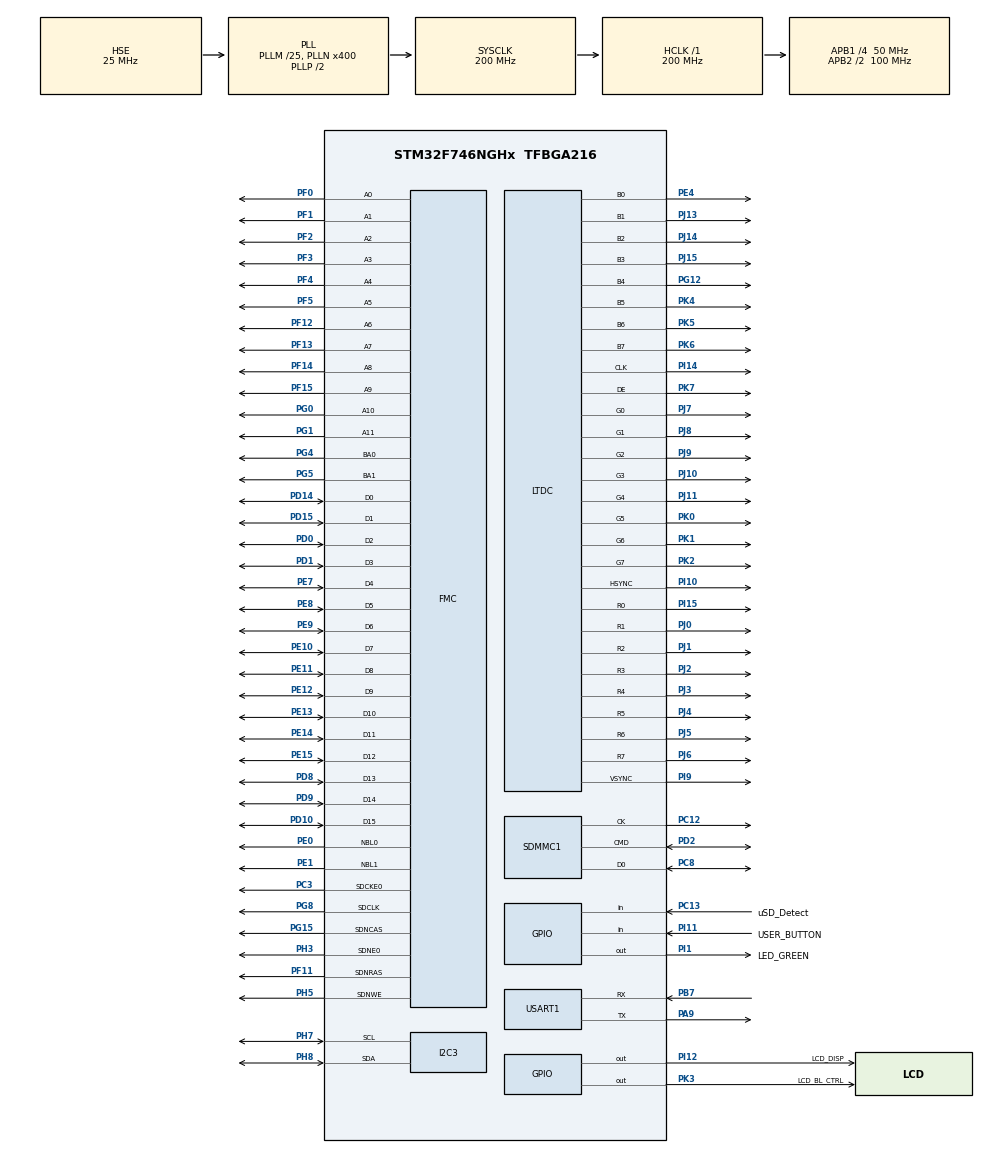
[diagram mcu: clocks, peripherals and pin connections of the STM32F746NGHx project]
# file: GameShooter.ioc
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CORTEX_M7.ART_ACCELERATOR_ENABLE=1
CORTEX_M7.AccessPermission-Cortex_Memory_Protection_Unit_Region0_Settings=MPU_REGION_NO_ACCESS
CORTEX_M7.AccessPermission-Cortex_Memory_Protection_Unit_Region1_Settings=MPU_REGION_FULL_ACCESS
CORTEX_M7.AccessPermission-Cortex_Memory_Protection_Unit_Region2_Settings=MPU_REGION_FULL_ACCESS
CORTEX_M7.BaseAddress-Cortex_Memory_Protection_Unit_Region0_Settings=0x00
CORTEX_M7.BaseAddress-Cortex_Memory_Protection_Unit_Region1_Settings=0xC0000000
CORTEX_M7.BaseAddress-Cortex_Memory_Protection_Unit_Region2_Settings=0xA0000000
CORTEX_M7.CPU_DCache=Enabled
CORTEX_M7.CPU_ICache=Enabled
CORTEX_M7.DisableExec-Cortex_Memory_Protection_Unit_Region0_Settings=MPU_INSTRUCTION_ACCESS_DISABLE
CORTEX_M7.DisableExec-Cortex_Memory_Protection_Unit_Region2_Settings=MPU_INSTRUCTION_ACCESS_DISABLE
CORTEX_M7.Enable-Cortex_Memory_Protection_Unit_Region0_Settings=MPU_REGION_ENABLE
CORTEX_M7.Enable-Cortex_Memory_Protection_Unit_Region1_Settings=MPU_REGION_ENABLE
CORTEX_M7.Enable-Cortex_Memory_Protection_Unit_Region2_Settings=MPU_REGION_ENABLE
CORTEX_M7.IsBufferable-Cortex_Memory_Protection_Unit_Region2_Settings=MPU_ACCESS_BUFFERABLE
CORTEX_M7.IsCacheable-Cortex_Memory_Protection_Unit_Region0_Settings=MPU_ACCESS_NOT_CACHEABLE
CORTEX_M7.IsCacheable-Cortex_Memory_Protection_Unit_Region1_Settings=MPU_ACCESS_CACHEABLE
CORTEX_M7.IsShareable-Cortex_Memory_Protection_Unit_Region0_Settings=MPU_ACCESS_SHAREABLE
CORTEX_M7.IsShareable-Cortex_Memory_Protection_Unit_Region2_Settings=MPU_ACCESS_SHAREABLE
CORTEX_M7.MPU_Control=MPU_PRIVILEGED_DEFAULT
CORTEX_M7.Size-Cortex_Memory_Protection_Unit_Region0_Settings=MPU_REGION_SIZE_4GB
CORTEX_M7.Size-Cortex_Memory_Protection_Unit_Region1_Settings=MPU_REGION_SIZE_32MB
CORTEX_M7.Size-Cortex_Memory_Protection_Unit_Region2_Settings=MPU_REGION_SIZE_8KB
CORTEX_M7.SubRegionDisable-Cortex_Memory_Protection_Unit_Region0_Settings=0x87
CORTEX_M7.SubRegionDisable-Cortex_Memory_Protection_Unit_Region1_Settings=0x00
CORTEX_M7.SubRegionDisable-Cortex_Memory_Protection_Unit_Region2_Settings=0x00
DMA2D.ColorMode=DMA2D_OUTPUT_RGB565
DMA2D.Mode=DMA2D_R2M
Dma.I2C3_RX.0.Direction=DMA_PERIPH_TO_MEMORY
Dma.I2C3_RX.0.FIFOMode=DMA_FIFOMODE_DISABLE
Dma.I2C3_RX.0.Instance=DMA1_Stream2
Dma.I2C3_RX.0.MemDataAlignment=DMA_MDATAALIGN_BYTE
Dma.I2C3_RX.0.MemInc=DMA_MINC_ENABLE
Dma.I2C3_RX.0.Mode=DMA_NORMAL
Dma.I2C3_RX.0.PeriphDataAlignment=DMA_PDATAALIGN_BYTE
Dma.I2C3_RX.0.PeriphInc=DMA_PINC_DISABLE
Dma.I2C3_RX.0.Priority=DMA_PRIORITY_LOW
Dma.I2C3_TX.1.Direction=DMA_MEMORY_TO_PERIPH
Dma.I2C3_TX.1.FIFOMode=DMA_FIFOMODE_DISABLE
Dma.I2C3_TX.1.Instance=DMA1_Stream4
Dma.I2C3_TX.1.MemDataAlignment=DMA_MDATAALIGN_BYTE
Dma.I2C3_TX.1.MemInc=DMA_MINC_ENABLE
Dma.I2C3_TX.1.Mode=DMA_NORMAL
Dma.I2C3_TX.1.PeriphDataAlignment=DMA_PDATAALIGN_BYTE
Dma.I2C3_TX.1.PeriphInc=DMA_PINC_DISABLE
Dma.I2C3_TX.1.Priority=DMA_PRIORITY_LOW
Dma.MEMTOMEM.2.Direction=DMA_MEMORY_TO_MEMORY
Dma.MEMTOMEM.2.FIFOMode=DMA_FIFOMODE_ENABLE
Dma.MEMTOMEM.2.FIFOThreshold=DMA_FIFO_THRESHOLD_FULL
Dma.MEMTOMEM.2.Instance=DMA2_Stream0
Dma.MEMTOMEM.2.MemBurst=DMA_MBURST_SINGLE
Dma.MEMTOMEM.2.MemDataAlignment=DMA_MDATAALIGN_WORD
Dma.MEMTOMEM.2.MemInc=DMA_MINC_ENABLE
Dma.MEMTOMEM.2.Mode=DMA_NORMAL
Dma.MEMTOMEM.2.PeriphBurst=DMA_PBURST_SINGLE
Dma.MEMTOMEM.2.PeriphDataAlignment=DMA_PDATAALIGN_WORD
Dma.MEMTOMEM.2.PeriphInc=DMA_PINC_ENABLE
Dma.MEMTOMEM.2.Priority=DMA_PRIORITY_HIGH
Dma.Request0=I2C3_RX
Dma.Request1=I2C3_TX
Dma.Request2=MEMTOMEM
Dma.Request3=SDMMC1_RX
Dma.Request4=SDMMC1_TX
Dma.SDMMC1_RX.3.Direction=DMA_PERIPH_TO_MEMORY
Dma.SDMMC1_RX.3.FIFOMode=DMA_FIFOMODE_ENABLE
Dma.SDMMC1_RX.3.FIFOThreshold=DMA_FIFO_THRESHOLD_FULL
Dma.SDMMC1_RX.3.Instance=DMA2_Stream3
Dma.SDMMC1_RX.3.MemBurst=DMA_MBURST_INC4
Dma.SDMMC1_RX.3.MemDataAlignment=DMA_MDATAALIGN_WORD
Dma.SDMMC1_RX.3.MemInc=DMA_MINC_ENABLE
Dma.SDMMC1_RX.3.Mode=DMA_PFCTRL
Dma.SDMMC1_RX.3.PeriphBurst=DMA_PBURST_INC4
Dma.SDMMC1_RX.3.PeriphDataAlignment=DMA_PDATAALIGN_WORD
Dma.SDMMC1_RX.3.PeriphInc=DMA_PINC_DISABLE
Dma.SDMMC1_RX.3.Priority=DMA_PRIORITY_LOW
Dma.SDMMC1_TX.4.Direction=DMA_MEMORY_TO_PERIPH
Dma.SDMMC1_TX.4.FIFOMode=DMA_FIFOMODE_ENABLE
Dma.SDMMC1_TX.4.FIFOThreshold=DMA_FIFO_THRESHOLD_FULL
Dma.SDMMC1_TX.4.Instance=DMA2_Stream6
Dma.SDMMC1_TX.4.MemBurst=DMA_MBURST_INC4
Dma.SDMMC1_TX.4.MemDataAlignment=DMA_MDATAALIGN_WORD
Dma.SDMMC1_TX.4.MemInc=DMA_MINC_ENABLE
Dma.SDMMC1_TX.4.Mode=DMA_PFCTRL
Dma.SDMMC1_TX.4.PeriphBurst=DMA_PBURST_INC4
Dma.SDMMC1_TX.4.PeriphDataAlignment=DMA_PDATAALIGN_WORD
Dma.SDMMC1_TX.4.PeriphInc=DMA_PINC_DISABLE
Dma.SDMMC1_TX.4.Priority=DMA_PRIORITY_LOW
FATFS.BSP.number=1
FATFS._FS_REENTRANT=1
FATFS._MAX_SS=4096
FATFS._USE_STRFUNC=0
FATFS0.BSP.STBoard=false
FATFS0.BSP.api=Unknown
FATFS0.BSP.instance=PC13
FATFS0.BSP.ip=GPIO
FATFS0.BSP.mode=Input
FATFS0.BSP.name=Detect_SDIO
FATFS0.BSP.solution=PC13
FMC.CASLatency1=FMC_SDRAM_CAS_LATENCY_2
FMC.ExitSelfRefreshDelay1=7
FMC.LoadToActiveDelay1=2
FMC.RCDDelay1=2
FMC.RPDelay1=2
FMC.ReadBurst1=FMC_SDRAM_RBURST_ENABLE
FMC.RowCycleDelay1=7
FMC.SDClockPeriod1=FMC_SDRAM_CLOCK_PERIOD_2
FMC.SelfRefreshTime1=4
FMC.WriteRecoveryTime1=3
FREERTOS.INCLUDE_vTaskDelayUntil=1
FREERTOS.Tasks01=mainGameTask,0,1280,StartMainGameTask,Default,NULL,Dynamic,NULL,NULL;touchscreenTask,2,128,StartTouchscreenTask,Default,NULL,Dynamic,NULL,NULL
FREERTOS.configTOTAL_HEAP_SIZE=32720
FREERTOS.configUSE_NEWLIB_REENTRANT=1
I2C3.OwnAddress=112
I2C3.Timing=0x00C0EAFF
LTDC.ActiveH=272
LTDC.ActiveW=480
LTDC.Alpha_L0=255
LTDC.BlendingFactor1_L0=LTDC_BLENDING_FACTOR1_PAxCA
LTDC.BlendingFactor1_L1=LTDC_BLENDING_FACTOR1_PAxCA
LTDC.BlendingFactor2_L0=LTDC_BLENDING_FACTOR2_PAxCA
LTDC.BlendingFactor2_L1=LTDC_BLENDING_FACTOR2_PAxCA
LTDC.DEPolarity=LTDC_DEPOLARITY_AL
LTDC.FBStartAdress_L0=0
LTDC.HBP=13
LTDC.HFP=32
LTDC.HSPolarity=LTDC_HSPOLARITY_AL
LTDC.HSync=41
LTDC.ImageHeight_L0=272
LTDC.ImageHeight_L1=272
LTDC.ImageWidth_L0=480
LTDC.ImageWidth_L1=480
LTDC.Layers=0
LTDC.PixelFormat_L0=LTDC_PIXEL_FORMAT_RGB565
LTDC.VBP=2
LTDC.VFP=2
LTDC.VSPolarity=LTDC_VSPOLARITY_AL
LTDC.VSync=10
LTDC.WindowX1_L0=480
LTDC.WindowX1_L1=480
LTDC.WindowY1_L0=272
LTDC.WindowY1_L1=272
Mcu.Family=STM32F7
Mcu.Name=STM32F746NGHx
Mcu.Package=TFBGA216
NVIC.DMA1_Stream2_IRQn=true\:5\:0\:false\:false\:true\:true\:false\:true\:true
NVIC.DMA1_Stream4_IRQn=true\:5\:0\:false\:false\:true\:true\:false\:true\:true
NVIC.DMA2D_IRQn=true\:5\:0\:false\:false\:true\:true\:true\:true\:true
NVIC.DMA2_Stream0_IRQn=true\:5\:0\:true\:false\:true\:true\:true\:true\:true
NVIC.DMA2_Stream3_IRQn=true\:5\:0\:false\:false\:true\:true\:false\:true\:true
NVIC.DMA2_Stream6_IRQn=true\:5\:0\:false\:false\:true\:true\:false\:true\:true
NVIC.LTDC_IRQn=true\:5\:0\:false\:false\:true\:true\:true\:true\:true
NVIC.PriorityGroup=NVIC_PRIORITYGROUP_4
NVIC.SDMMC1_IRQn=true\:5\:0\:false\:false\:true\:true\:true\:true\:true
NVIC.TIM1_UP_TIM10_IRQn=true\:15\:0\:false\:false\:true\:false\:false\:true\:true
NVIC.TimeBase=TIM1_UP_TIM10_IRQn
NVIC.TimeBaseIP=TIM1
PA13.Mode=Serial_Wire
PA13.Signal=SYS_JTMS-SWDIO
PA14.Mode=Serial_Wire
PA14.Signal=SYS_JTCK-SWCLK
PA9.Mode=Asynchronous
PA9.Signal=USART1_TX
PB7.Mode=Asynchronous
PB7.Signal=USART1_RX
PC12.Mode=SD_1_bit
PC12.Signal=SDMMC1_CK
PC13.GPIO_Label=uSD_Detect
PC13.Signal=GPIO_Input
PC3.GPIO_PuPd=GPIO_PULLUP
PC3.Mode=SdramChipSelect1_1
PC3.Signal=FMC_SDCKE0
PC8.GPIO_PuPd=GPIO_PULLUP
PC8.Mode=SD_1_bit
PC8.Signal=SDMMC1_D0
PD0.GPIO_PuPd=GPIO_PULLUP
PD0.Signal=FMC_D2_DA2
PD1.GPIO_PuPd=GPIO_PULLUP
PD1.Signal=FMC_D3_DA3
PD10.GPIO_PuPd=GPIO_PULLUP
PD10.Signal=FMC_D15_DA15
PD14.GPIO_PuPd=GPIO_PULLUP
PD14.Signal=FMC_D0_DA0
PD15.GPIO_PuPd=GPIO_PULLUP
PD15.Signal=FMC_D1_DA1
PD2.GPIO_PuPd=GPIO_PULLUP
PD2.Mode=SD_1_bit
PD2.Signal=SDMMC1_CMD
PD8.GPIO_PuPd=GPIO_PULLUP
PD8.Signal=FMC_D13_DA13
PD9.GPIO_PuPd=GPIO_PULLUP
PD9.Signal=FMC_D14_DA14
PE0.GPIO_PuPd=GPIO_PULLUP
PE0.Signal=FMC_NBL0
PE1.GPIO_PuPd=GPIO_PULLUP
PE1.Signal=FMC_NBL1
PE10.GPIO_PuPd=GPIO_PULLUP
PE10.Signal=FMC_D7_DA7
PE11.GPIO_PuPd=GPIO_PULLUP
PE11.Signal=FMC_D8_DA8
PE12.GPIO_PuPd=GPIO_PULLUP
PE12.Signal=FMC_D9_DA9
PE13.GPIO_PuPd=GPIO_PULLUP
PE13.Signal=FMC_D10_DA10
PE14.GPIO_PuPd=GPIO_PULLUP
PE14.Signal=FMC_D11_DA11
PE15.GPIO_PuPd=GPIO_PULLUP
PE15.Signal=FMC_D12_DA12
PE4.GPIO_Speed=GPIO_SPEED_FREQ_VERY_HIGH
PE4.Mode=RGB888
PE4.Signal=LTDC_B0
PE7.GPIO_PuPd=GPIO_PULLUP
PE7.Signal=FMC_D4_DA4
PE8.GPIO_PuPd=GPIO_PULLUP
PE8.Signal=FMC_D5_DA5
PE9.GPIO_PuPd=GPIO_PULLUP
PE9.Signal=FMC_D6_DA6
PF0.GPIO_PuPd=GPIO_PULLUP
PF0.Signal=FMC_A0
PF1.GPIO_PuPd=GPIO_PULLUP
PF1.Signal=FMC_A1
PF11.GPIO_PuPd=GPIO_PULLUP
PF11.Signal=FMC_SDNRAS
PF12.GPIO_PuPd=GPIO_PULLUP
PF12.Signal=FMC_A6
PF13.GPIO_PuPd=GPIO_PULLUP
PF13.Signal=FMC_A7
PF14.GPIO_PuPd=GPIO_PULLUP
PF14.Signal=FMC_A8
PF15.GPIO_PuPd=GPIO_PULLUP
PF15.Signal=FMC_A9
PF2.GPIO_PuPd=GPIO_PULLUP
PF2.Signal=FMC_A2
PF3.GPIO_PuPd=GPIO_PULLUP
PF3.Signal=FMC_A3
PF4.GPIO_PuPd=GPIO_PULLUP
PF4.Signal=FMC_A4
PF5.GPIO_PuPd=GPIO_PULLUP
PF5.Signal=FMC_A5
PG0.GPIO_PuPd=GPIO_PULLUP
PG0.Signal=FMC_A10
PG1.GPIO_PuPd=GPIO_PULLUP
PG1.Signal=FMC_A11
PG12.GPIO_Speed=GPIO_SPEED_FREQ_VERY_HIGH
PG12.Mode=RGB888
PG12.Signal=LTDC_B4
PG15.GPIO_PuPd=GPIO_PULLUP
PG15.Signal=FMC_SDNCAS
PG4.GPIO_PuPd=GPIO_PULLUP
PG4.Signal=FMC_A14_BA0
PG5.GPIO_PuPd=GPIO_PULLUP
PG5.Signal=FMC_A15_BA1
PG8.GPIO_PuPd=GPIO_PULLUP
PG8.Signal=FMC_SDCLK
PH0/OSC_IN.Mode=HSE-External-Oscillator
PH0/OSC_IN.Signal=RCC_OSC_IN
PH1/OSC_OUT.Mode=HSE-External-Oscillator
PH1/OSC_OUT.Signal=RCC_OSC_OUT
PH3.GPIO_PuPd=GPIO_PULLUP
PH3.Mode=SdramChipSelect1_1
PH3.Signal=FMC_SDNE0
PH5.GPIO_PuPd=GPIO_PULLUP
PH5.Signal=FMC_SDNWE
PH7.Mode=I2C
PH7.Signal=I2C3_SCL
PH8.Mode=I2C
PH8.Signal=I2C3_SDA
PI1.GPIO_Label=LED_GREEN
PI1.Signal=GPIO_Output
PI10.GPIO_Speed=GPIO_SPEED_FREQ_VERY_HIGH
PI10.Mode=RGB888
PI10.Signal=LTDC_HSYNC
PI11.GPIO_Label=USER_BUTTON
PI11.Signal=GPIO_Input
PI12.GPIO_Label=LCD_DISP
PI12.GPIO_Speed=GPIO_SPEED_FREQ_VERY_HIGH
PI12.PinState=GPIO_PIN_SET
PI12.Signal=GPIO_Output
PI14.GPIO_Speed=GPIO_SPEED_FREQ_VERY_HIGH
PI14.Mode=RGB888
PI14.Signal=LTDC_CLK
PI15.GPIO_Speed=GPIO_SPEED_FREQ_VERY_HIGH
PI15.Mode=RGB888
PI15.Signal=LTDC_R0
PI9.GPIO_Speed=GPIO_SPEED_FREQ_VERY_HIGH
PI9.Mode=RGB888
PI9.Signal=LTDC_VSYNC
PJ0.GPIO_Speed=GPIO_SPEED_FREQ_VERY_HIGH
PJ0.Mode=RGB888
PJ0.Signal=LTDC_R1
PJ1.GPIO_Speed=GPIO_SPEED_FREQ_VERY_HIGH
PJ1.Mode=RGB888
PJ1.Signal=LTDC_R2
PJ10.GPIO_Speed=GPIO_SPEED_FREQ_VERY_HIGH
PJ10.Mode=RGB888
PJ10.Signal=LTDC_G3
PJ11.GPIO_Speed=GPIO_SPEED_FREQ_VERY_HIGH
PJ11.Mode=RGB888
PJ11.Signal=LTDC_G4
PJ13.GPIO_Speed=GPIO_SPEED_FREQ_VERY_HIGH
PJ13.Mode=RGB888
PJ13.Signal=LTDC_B1
PJ14.GPIO_Speed=GPIO_SPEED_FREQ_VERY_HIGH
PJ14.Mode=RGB888
PJ14.Signal=LTDC_B2
PJ15.GPIO_Speed=GPIO_SPEED_FREQ_VERY_HIGH
PJ15.Mode=RGB888
PJ15.Signal=LTDC_B3
PJ2.GPIO_Speed=GPIO_SPEED_FREQ_VERY_HIGH
PJ2.Mode=RGB888
PJ2.Signal=LTDC_R3
PJ3.GPIO_Speed=GPIO_SPEED_FREQ_VERY_HIGH
PJ3.Mode=RGB888
PJ3.Signal=LTDC_R4
PJ4.GPIO_Speed=GPIO_SPEED_FREQ_VERY_HIGH
PJ4.Mode=RGB888
PJ4.Signal=LTDC_R5
PJ5.GPIO_Speed=GPIO_SPEED_FREQ_VERY_HIGH
PJ5.Mode=RGB888
PJ5.Signal=LTDC_R6
PJ6.GPIO_Speed=GPIO_SPEED_FREQ_VERY_HIGH
PJ6.Mode=RGB888
PJ6.Signal=LTDC_R7
PJ7.GPIO_Speed=GPIO_SPEED_FREQ_VERY_HIGH
PJ7.Mode=RGB888
PJ7.Signal=LTDC_G0
PJ8.GPIO_Speed=GPIO_SPEED_FREQ_VERY_HIGH
PJ8.Mode=RGB888
PJ8.Signal=LTDC_G1
PJ9.GPIO_Speed=GPIO_SPEED_FREQ_VERY_HIGH
PJ9.Mode=RGB888
PJ9.Signal=LTDC_G2
PK0.GPIO_Speed=GPIO_SPEED_FREQ_VERY_HIGH
PK0.Mode=RGB888
PK0.Signal=LTDC_G5
PK1.GPIO_Speed=GPIO_SPEED_FREQ_VERY_HIGH
PK1.Mode=RGB888
PK1.Signal=LTDC_G6
PK2.GPIO_Speed=GPIO_SPEED_FREQ_VERY_HIGH
PK2.Mode=RGB888
PK2.Signal=LTDC_G7
PK3.GPIO_Label=LCD_BL_CTRL
PK3.GPIO_Speed=GPIO_SPEED_FREQ_VERY_HIGH
PK3.PinState=GPIO_PIN_SET
PK3.Signal=GPIO_Output
PK4.GPIO_Speed=GPIO_SPEED_FREQ_VERY_HIGH
PK4.Mode=RGB888
PK4.Signal=LTDC_B5
PK5.GPIO_Speed=GPIO_SPEED_FREQ_VERY_HIGH
PK5.Mode=RGB888
PK5.Signal=LTDC_B6
PK6.GPIO_Speed=GPIO_SPEED_FREQ_VERY_HIGH
PK6.Mode=RGB888
PK6.Signal=LTDC_B7
PK7.GPIO_Speed=GPIO_SPEED_FREQ_VERY_HIGH
PK7.Mode=RGB888
PK7.Signal=LTDC_DE
ProjectManager.HeapSize=0x2000
ProjectManager.StackSize=0x4000
ProjectManager.TargetToolchain=STM32CubeIDE
RCC.AHBFreq_Value=200000000
RCC.APB1CLKDivider=RCC_HCLK_DIV4
RCC.APB1Freq_Value=50000000
RCC.APB1TimFreq_Value=100000000
RCC.APB2CLKDivider=RCC_HCLK_DIV2
RCC.APB2Freq_Value=100000000
RCC.APB2TimFreq_Value=200000000
RCC.CortexFreq_Value=200000000
RCC.HCLKFreq_Value=200000000
RCC.HSE_VALUE=25000000
RCC.HSI_VALUE=16000000
RCC.LSE_VALUE=32768
RCC.PLL48CLockSelection=RCC_CLK48SOURCE_PLLSAIP
RCC.PLLI2SN=100
RCC.PLLM=25
RCC.PLLN=400
RCC.PLLQ=8
RCC.PLLSAIN=384
RCC.PLLSAIP=RCC_PLLSAIP_DIV8
RCC.PLLSAIR=5
RCC.PLLSAIRDiv=RCC_PLLSAIDIVR_8
RCC.PLLSourceVirtual=RCC_PLLSOURCE_HSE
RCC.SDMMCClockSelection=RCC_SDMMC1CLKSOURCE_CLK48
RCC.SYSCLKFreq_VALUE=200000000
RCC.SYSCLKSource=RCC_SYSCLKSOURCE_PLLCLK
RCC.USBFreq_Value=48000000
RCC.VCOOutputFreq_Value=400000000
RCC.VDD_VALUE=3.3
SH.FMC_A0.0=FMC_A0,12b-sda1
SH.FMC_A1.0=FMC_A1,12b-sda1
SH.FMC_A10.0=FMC_A10,12b-sda1
SH.FMC_A11.0=FMC_A11,12b-sda1
SH.FMC_A14_BA0.0=FMC_BA0,FourSdramBanks1
SH.FMC_A15_BA1.0=FMC_BA1,FourSdramBanks1
SH.FMC_A2.0=FMC_A2,12b-sda1
SH.FMC_A3.0=FMC_A3,12b-sda1
SH.FMC_A4.0=FMC_A4,12b-sda1
SH.FMC_A5.0=FMC_A5,12b-sda1
SH.FMC_A6.0=FMC_A6,12b-sda1
SH.FMC_A7.0=FMC_A7,12b-sda1
SH.FMC_A8.0=FMC_A8,12b-sda1
SH.FMC_A9.0=FMC_A9,12b-sda1
SH.FMC_D0_DA0.0=FMC_D0,sd-16b-d1
SH.FMC_D10_DA10.0=FMC_D10,sd-16b-d1
SH.FMC_D11_DA11.0=FMC_D11,sd-16b-d1
SH.FMC_D12_DA12.0=FMC_D12,sd-16b-d1
SH.FMC_D13_DA13.0=FMC_D13,sd-16b-d1
SH.FMC_D14_DA14.0=FMC_D14,sd-16b-d1
SH.FMC_D15_DA15.0=FMC_D15,sd-16b-d1
SH.FMC_D1_DA1.0=FMC_D1,sd-16b-d1
SH.FMC_D2_DA2.0=FMC_D2,sd-16b-d1
SH.FMC_D3_DA3.0=FMC_D3,sd-16b-d1
SH.FMC_D4_DA4.0=FMC_D4,sd-16b-d1
SH.FMC_D5_DA5.0=FMC_D5,sd-16b-d1
SH.FMC_D6_DA6.0=FMC_D6,sd-16b-d1
SH.FMC_D7_DA7.0=FMC_D7,sd-16b-d1
SH.FMC_D8_DA8.0=FMC_D8,sd-16b-d1
SH.FMC_D9_DA9.0=FMC_D9,sd-16b-d1
SH.FMC_NBL0.0=FMC_NBL0,Sd2ByteEnable1
SH.FMC_NBL1.0=FMC_NBL1,Sd2ByteEnable1
SH.FMC_SDCLK.0=FMC_SDCLK,12b-sda1
SH.FMC_SDNCAS.0=FMC_SDNCAS,12b-sda1
SH.FMC_SDNRAS.0=FMC_SDNRAS,12b-sda1
SH.FMC_SDNWE.0=FMC_SDNWE,12b-sda1
USART1.VirtualMode-Asynchronous=VM_ASYNC
VP_DMA2D_VS_DMA2D.Mode=DMA2D_Activate
VP_FATFS_VS_SDIO.Mode=SDIO
VP_FREERTOS_VS_CMSIS_V1.Mode=CMSIS_V1
VP_RNG_VS_RNG.Mode=RNG_Activate
VP_SYS_VS_tim1.Mode=TIM1
board=custom

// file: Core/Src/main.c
/* USER CODE BEGIN Header */
/**
  ******************************************************************************
  * @file           : main.c
  * @brief          : Main program body
  ******************************************************************************
  * @attention
  *
  * Copyright (c) 2023 STMicroelectronics.
  * All rights reserved.
  *
  * This software is licensed under terms that can be found in the LICENSE file
  * in the root directory of this software component.
  * If no LICENSE file comes with this software, it is provided AS-IS.
  *
  ******************************************************************************
  */
/* USER CODE END Header */
#include "main.h"
#include "cmsis_os.h"
#include "dma.h"
#include "dma2d.h"
#include "fatfs.h"
#include "i2c.h"
#include "ltdc.h"
#include "rng.h"
#include "sdmmc.h"
#include "usart.h"
#include "gpio.h"
#include "fmc.h"

/* USER CODE BEGIN Includes */
#include <GUI.h>
#include <stdio.h>
#include "sdram.h"
#include "ft5336.h"
/* USER CODE END Includes */

void SystemClock_Config(void);
void PeriphCommonClock_Config(void);
static void MPU_Initialize(void);
static void MPU_Config(void);
void MX_FREERTOS_Init(void);

int main(void)
{

  /* Enable I-Cache---------------------------------------------------------*/
  SCB_EnableICache();

  /* Enable D-Cache---------------------------------------------------------*/
  SCB_EnableDCache();

  /* MCU Configuration--------------------------------------------------------*/

  /* Reset of all peripherals, Initializes the Flash interface and the Systick. */
  HAL_Init();

  /* MPU Configuration--------------------------------------------------------*/
  MPU_Config();

  /* Configure the system clock */
  SystemClock_Config();

/* Configure the peripherals common clocks */
  PeriphCommonClock_Config();

  /* Initialize all configured peripherals */
  MX_GPIO_Init();
  MX_DMA_Init();
  MX_FMC_Init();
  MX_LTDC_Init();
  MX_USART1_UART_Init();
  MX_SDMMC1_SD_Init();
  MX_DMA2D_Init();
  MX_FATFS_Init();
  MX_RNG_Init();
  MX_I2C3_Init();
  /* USER CODE BEGIN 2 */
  FATFS_UnLinkDriver(SDPath);
  Touch_Init();
  SDRAM_Init(&hsdram1);
  /* Enable CRC to Unlock GUI */
  __HAL_RCC_CRC_CLK_ENABLE();
  GUI_Init();
  /* Set memdev multibuffering */
  GUI_MEMDEV_MULTIBUF_Enable(1);

  GUI_SetBkColor(GUI_BLUE_TEAL);
  GUI_Clear();
  /* USER CODE END 2 */

  /* Call init function for freertos objects (in freertos.c) */
  MX_FREERTOS_Init();

  /* Start scheduler */
  osKernelStart();

  /* We should never get here as control is now taken by the scheduler */
  /* Infinite loop */
  while (1)
  {

  }
}

void SystemClock_Config(void)
{
  RCC_OscInitTypeDef RCC_OscInitStruct = {0};
  RCC_ClkInitTypeDef RCC_ClkInitStruct = {0};

  /** Configure the main internal regulator output voltage
  */
  __HAL_RCC_PWR_CLK_ENABLE();
  __HAL_PWR_VOLTAGESCALING_CONFIG(PWR_REGULATOR_VOLTAGE_SCALE1);

  /** Initializes the RCC Oscillators according to the specified parameters
  * in the RCC_OscInitTypeDef structure.
  */
  RCC_OscInitStruct.OscillatorType = RCC_OSCILLATORTYPE_HSE;
  RCC_OscInitStruct.HSEState = RCC_HSE_ON;
  RCC_OscInitStruct.PLL.PLLState = RCC_PLL_ON;
  RCC_OscInitStruct.PLL.PLLSource = RCC_PLLSOURCE_HSE;
  RCC_OscInitStruct.PLL.PLLM = 25;
  RCC_OscInitStruct.PLL.PLLN = 400;
  RCC_OscInitStruct.PLL.PLLP = RCC_PLLP_DIV2;
  RCC_OscInitStruct.PLL.PLLQ = 8;
  if (HAL_RCC_OscConfig(&RCC_OscInitStruct) != HAL_OK)
  {
    Error_Handler();
  }

  /** Activate the Over-Drive mode
  */
  if (HAL_PWREx_EnableOverDrive() != HAL_OK)
  {
    Error_Handler();
  }

  /** Initializes the CPU, AHB and APB buses clocks
  */
  RCC_ClkInitStruct.ClockType = RCC_CLOCKTYPE_HCLK|RCC_CLOCKTYPE_SYSCLK
                              |RCC_CLOCKTYPE_PCLK1|RCC_CLOCKTYPE_PCLK2;
  RCC_ClkInitStruct.SYSCLKSource = RCC_SYSCLKSOURCE_PLLCLK;
  RCC_ClkInitStruct.AHBCLKDivider = RCC_SYSCLK_DIV1;
  RCC_ClkInitStruct.APB1CLKDivider = RCC_HCLK_DIV4;
  RCC_ClkInitStruct.APB2CLKDivider = RCC_HCLK_DIV2;

  if (HAL_RCC_ClockConfig(&RCC_ClkInitStruct, FLASH_LATENCY_6) != HAL_OK)
  {
    Error_Handler();
  }
}

void PeriphCommonClock_Config(void)
{
  RCC_PeriphCLKInitTypeDef PeriphClkInitStruct = {0};

  /** Initializes the peripherals clock
  */
  PeriphClkInitStruct.PeriphClockSelection = RCC_PERIPHCLK_LTDC|RCC_PERIPHCLK_SDMMC1
                              |RCC_PERIPHCLK_CLK48;
  PeriphClkInitStruct.PLLSAI.PLLSAIN = 384;
  PeriphClkInitStruct.PLLSAI.PLLSAIR = 5;
  PeriphClkInitStruct.PLLSAI.PLLSAIQ = 2;
  PeriphClkInitStruct.PLLSAI.PLLSAIP = RCC_PLLSAIP_DIV8;
  PeriphClkInitStruct.PLLSAIDivQ = 1;
  PeriphClkInitStruct.PLLSAIDivR = RCC_PLLSAIDIVR_8;
  PeriphClkInitStruct.Clk48ClockSelection = RCC_CLK48SOURCE_PLLSAIP;
  PeriphClkInitStruct.Sdmmc1ClockSelection = RCC_SDMMC1CLKSOURCE_CLK48;
  if (HAL_RCCEx_PeriphCLKConfig(&PeriphClkInitStruct) != HAL_OK)
  {
    Error_Handler();
  }
}

/* MPU Configuration */

void MPU_Config(void)
{
  MPU_Region_InitTypeDef MPU_InitStruct = {0};

  /* Disables the MPU */
  HAL_MPU_Disable();

  /** Initializes and configures the Region and the memory to be protected
  */
  MPU_InitStruct.Enable = MPU_REGION_ENABLE;
  MPU_InitStruct.Number = MPU_REGION_NUMBER0;
  MPU_InitStruct.BaseAddress = 0x00;
  MPU_InitStruct.Size = MPU_REGION_SIZE_4GB;
  MPU_InitStruct.SubRegionDisable = 0x87;
  MPU_InitStruct.TypeExtField = MPU_TEX_LEVEL0;
  MPU_InitStruct.AccessPermission = MPU_REGION_NO_ACCESS;
  MPU_InitStruct.DisableExec = MPU_INSTRUCTION_ACCESS_DISABLE;
  MPU_InitStruct.IsShareable = MPU_ACCESS_SHAREABLE;
  MPU_InitStruct.IsCacheable = MPU_ACCESS_NOT_CACHEABLE;
  MPU_InitStruct.IsBufferable = MPU_ACCESS_NOT_BUFFERABLE;

  HAL_MPU_ConfigRegion(&MPU_InitStruct);

  /** Initializes and configures the Region and the memory to be protected
  */
  MPU_InitStruct.Number = MPU_REGION_NUMBER1;
  MPU_InitStruct.BaseAddress = 0xC0000000;
  MPU_InitStruct.Size = MPU_REGION_SIZE_32MB;
  MPU_InitStruct.SubRegionDisable = 0x00;
  MPU_InitStruct.AccessPermission = MPU_REGION_FULL_ACCESS;
  MPU_InitStruct.DisableExec = MPU_INSTRUCTION_ACCESS_ENABLE;
  MPU_InitStruct.IsShareable = MPU_ACCESS_NOT_SHAREABLE;
  MPU_InitStruct.IsCacheable = MPU_ACCESS_CACHEABLE;

  HAL_MPU_ConfigRegion(&MPU_InitStruct);

  /** Initializes and configures the Region and the memory to be protected
  */
  MPU_InitStruct.Number = MPU_REGION_NUMBER2;
  MPU_InitStruct.BaseAddress = 0xA0000000;
  MPU_InitStruct.Size = MPU_REGION_SIZE_8KB;
  MPU_InitStruct.DisableExec = MPU_INSTRUCTION_ACCESS_DISABLE;
  MPU_InitStruct.IsShareable = MPU_ACCESS_SHAREABLE;
  MPU_InitStruct.IsCacheable = MPU_ACCESS_NOT_CACHEABLE;
  MPU_InitStruct.IsBufferable = MPU_ACCESS_BUFFERABLE;

  HAL_MPU_ConfigRegion(&MPU_InitStruct);
  /* Enables the MPU */
  HAL_MPU_Enable(MPU_PRIVILEGED_DEFAULT);

}

void HAL_TIM_PeriodElapsedCallback(TIM_HandleTypeDef *htim)
{
  if (htim->Instance == TIM1) {
    HAL_IncTick();
  }
}

void Error_Handler(void)
{
  /* USER CODE BEGIN Error_Handler_Debug */
  GUI_SelectLayer(1);
  GUI_SetBkColor(GUI_RED);
  GUI_Clear();
  /* User can add his own implementation to report the HAL error return state */
  __disable_irq();
  while (1)
  {
  }
  /* USER CODE END Error_Handler_Debug */
}

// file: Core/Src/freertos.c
/* USER CODE BEGIN Header */
/**
  ******************************************************************************
  * File Name          : freertos.c
  * Description        : Code for freertos applications
  ******************************************************************************
  * @attention
  *
  * Copyright (c) 2023 STMicroelectronics.
  * All rights reserved.
  *
  * This software is licensed under terms that can be found in the LICENSE file
  * in the root directory of this software component.
  * If no LICENSE file comes with this software, it is provided AS-IS.
  *
  ******************************************************************************
  */
/* USER CODE END Header */

#include "FreeRTOS.h"
#include "task.h"
#include "main.h"
#include "cmsis_os.h"

/* USER CODE BEGIN Includes */
#include <stdio.h>
#include <stdlib.h>
#include "ft5336.h"
#include "CtoCppBridge.hpp"
/* USER CODE END Includes */

/* USER CODE BEGIN Variables */
TS_StateTypeDef g_tsState;
/* USER CODE END Variables */
osThreadId mainGameTaskHandle;
osThreadId touchscreenTaskHandle;

void StartMainGameTask(void const * argument);
void StartTouchscreenTask(void const * argument);

void MX_FREERTOS_Init(void); /* (MISRA C 2004 rule 8.1) */

/* GetIdleTaskMemory prototype (linked to static allocation support) */
void vApplicationGetIdleTaskMemory( StaticTask_t **ppxIdleTaskTCBBuffer, StackType_t **ppxIdleTaskStackBuffer, uint32_t *pulIdleTaskStackSize );

/* USER CODE BEGIN GET_IDLE_TASK_MEMORY */
static StaticTask_t xIdleTaskTCBBuffer;
static StackType_t xIdleStack[configMINIMAL_STACK_SIZE];

void vApplicationGetIdleTaskMemory( StaticTask_t **ppxIdleTaskTCBBuffer, StackType_t **ppxIdleTaskStackBuffer, uint32_t *pulIdleTaskStackSize )
{
  *ppxIdleTaskTCBBuffer = &xIdleTaskTCBBuffer;
  *ppxIdleTaskStackBuffer = &xIdleStack[0];
  *pulIdleTaskStackSize = configMINIMAL_STACK_SIZE;
  /* place for user code */
}
/* USER CODE END GET_IDLE_TASK_MEMORY */

void MX_FREERTOS_Init(void) {

  /* Create the thread(s) */
  /* definition and creation of mainGameTask */
  osThreadDef(mainGameTask, StartMainGameTask, osPriorityNormal, 0, 1280);
  mainGameTaskHandle = osThreadCreate(osThread(mainGameTask), NULL);

  /* definition and creation of touchscreenTask */
  osThreadDef(touchscreenTask, StartTouchscreenTask, osPriorityHigh, 0, 128);
  touchscreenTaskHandle = osThreadCreate(osThread(touchscreenTask), NULL);

}

void StartMainGameTask(void const * argument)
{
  /* USER CODE BEGIN StartMainGameTask */
  EventLoopC();
  /* USER CODE END StartMainGameTask */
}

void StartTouchscreenTask(void const * argument)
{
  /* USER CODE BEGIN StartTouchscreenTask */
  uint32_t tickCount = osKernelSysTick();
  /* Infinite loop */
  for(;;)
  {
    TS_GetState(&g_tsState);
    osDelayUntil(&tickCount, 50);
  }
  /* USER CODE END StartTouchscreenTask */
}
